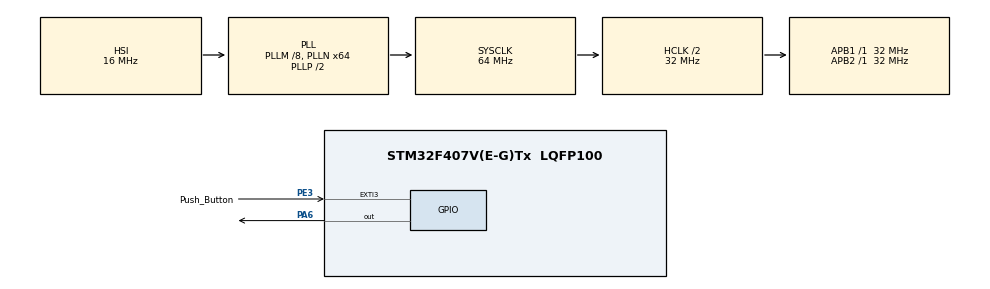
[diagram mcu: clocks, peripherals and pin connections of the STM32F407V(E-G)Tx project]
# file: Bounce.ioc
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Mcu.Family=STM32F4
Mcu.Name=STM32F407V(E-G)Tx
Mcu.Package=LQFP100
NVIC.EXTI3_IRQn=true\:0\:0\:false\:false\:true\:true\:true\:true
NVIC.PriorityGroup=NVIC_PRIORITYGROUP_4
NVIC.TIM1_BRK_TIM9_IRQn=true\:0\:0\:false\:false\:true\:true\:true\:true
NVIC.TIM1_CC_IRQn=true\:0\:0\:false\:false\:true\:true\:true\:true
NVIC.TIM1_TRG_COM_TIM11_IRQn=true\:0\:0\:false\:false\:true\:true\:true\:true
NVIC.TIM1_UP_TIM10_IRQn=true\:0\:0\:false\:false\:true\:true\:true\:true
PA13.Mode=Serial_Wire
PA13.Signal=SYS_JTMS-SWDIO
PA14.Mode=Serial_Wire
PA14.Signal=SYS_JTCK-SWCLK
PA6.PinState=GPIO_PIN_SET
PA6.Signal=GPIO_Output
PE3.GPIO_Label=Push_Button
PE3.GPIO_ModeDefaultEXTI=GPIO_MODE_IT_FALLING
PE3.GPIO_PuPd=GPIO_PULLUP
PE3.Signal=GPXTI3
PH0-OSC_IN.Mode=HSE-External-Oscillator
PH0-OSC_IN.Signal=RCC_OSC_IN
PH1-OSC_OUT.Mode=HSE-External-Oscillator
PH1-OSC_OUT.Signal=RCC_OSC_OUT
ProjectManager.HeapSize=0x200
ProjectManager.StackSize=0x400
ProjectManager.TargetToolchain=STM32CubeIDE
RCC.48MHZClocksFreq_Value=32000000
RCC.AHBCLKDivider=RCC_SYSCLK_DIV2
RCC.AHBFreq_Value=32000000
RCC.APB1Freq_Value=32000000
RCC.APB1TimFreq_Value=32000000
RCC.APB2Freq_Value=32000000
RCC.APB2TimFreq_Value=32000000
RCC.CortexFreq_Value=32000000
RCC.HCLKFreq_Value=32000000
RCC.HSE_VALUE=8000000
RCC.HSI_VALUE=16000000
RCC.LSE_VALUE=32768
RCC.PLLM=8
RCC.PLLN=64
RCC.SYSCLKFreq_VALUE=64000000
RCC.SYSCLKSource=RCC_SYSCLKSOURCE_PLLCLK
RCC.VCOOutputFreq_Value=128000000
TIM1.Period=50
TIM1.Prescaler=31999
VP_TIM1_VS_ClockSourceINT.Mode=Internal
VP_TIM1_VS_OPM.Mode=OPM_bit
board=custom

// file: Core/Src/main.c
/* USER CODE BEGIN Header */
/**
  ******************************************************************************
  * @file           : main.c
  * @brief          : Main program body
  ******************************************************************************
  * @attention
  *
  * Copyright (c) 2025 STMicroelectronics.
  * All rights reserved.
  *
  * This software is licensed under terms that can be found in the LICENSE file
  * in the root directory of this software component.
  * If no LICENSE file comes with this software, it is provided AS-IS.
  *
  ******************************************************************************
  */
/* USER CODE END Header */
#include "main.h"

/* USER CODE BEGIN Includes */
#include <stdbool.h>
/* USER CODE END Includes */

TIM_HandleTypeDef htim1;

void SystemClock_Config(void);
static void MX_GPIO_Init(void);
static void MX_TIM1_Init(void);
/* USER CODE BEGIN PFP */
bool state = true;
void HAL_GPIO_EXTI_Callback(uint16_t GPIO_Pin)
{
	if (GPIO_Pin == Push_Button_Pin && state == true)
	{
		HAL_TIM_Base_Start_IT(&htim1);
		state = false;
	}
	else
	{
		__NOP();
	}

	return;
}

void HAL_TIM_PeriodElapsedCallback(TIM_HandleTypeDef *htim)
{
	UNUSED(htim);

	if (HAL_GPIO_ReadPin(Push_Button_GPIO_Port, Push_Button_Pin) == GPIO_PIN_RESET)
	{
		HAL_GPIO_TogglePin(GPIOA, GPIO_PIN_6);
		state = true;
		HAL_TIM_Base_Stop_IT(&htim1);
	}

	return;
}
/* USER CODE END PFP */

int main(void)
{

  /* MCU Configuration--------------------------------------------------------*/

  /* Reset of all peripherals, Initializes the Flash interface and the Systick. */
  HAL_Init();

  /* Configure the system clock */
  SystemClock_Config();

  /* Initialize all configured peripherals */
  MX_GPIO_Init();
  MX_TIM1_Init();

  /* Infinite loop */
  while (1)
  {

  }
}

void SystemClock_Config(void)
{
  RCC_OscInitTypeDef RCC_OscInitStruct = {0};
  RCC_ClkInitTypeDef RCC_ClkInitStruct = {0};

  /** Configure the main internal regulator output voltage
  */
  __HAL_RCC_PWR_CLK_ENABLE();
  __HAL_PWR_VOLTAGESCALING_CONFIG(PWR_REGULATOR_VOLTAGE_SCALE1);

  /** Initializes the RCC Oscillators according to the specified parameters
  * in the RCC_OscInitTypeDef structure.
  */
  RCC_OscInitStruct.OscillatorType = RCC_OSCILLATORTYPE_HSI;
  RCC_OscInitStruct.HSIState = RCC_HSI_ON;
  RCC_OscInitStruct.HSICalibrationValue = RCC_HSICALIBRATION_DEFAULT;
  RCC_OscInitStruct.PLL.PLLState = RCC_PLL_ON;
  RCC_OscInitStruct.PLL.PLLSource = RCC_PLLSOURCE_HSI;
  RCC_OscInitStruct.PLL.PLLM = 8;
  RCC_OscInitStruct.PLL.PLLN = 64;
  RCC_OscInitStruct.PLL.PLLP = RCC_PLLP_DIV2;
  RCC_OscInitStruct.PLL.PLLQ = 4;
  if (HAL_RCC_OscConfig(&RCC_OscInitStruct) != HAL_OK)
  {
    Error_Handler();
  }

  /** Initializes the CPU, AHB and APB buses clocks
  */
  RCC_ClkInitStruct.ClockType = RCC_CLOCKTYPE_HCLK|RCC_CLOCKTYPE_SYSCLK
                              |RCC_CLOCKTYPE_PCLK1|RCC_CLOCKTYPE_PCLK2;
  RCC_ClkInitStruct.SYSCLKSource = RCC_SYSCLKSOURCE_PLLCLK;
  RCC_ClkInitStruct.AHBCLKDivider = RCC_SYSCLK_DIV2;
  RCC_ClkInitStruct.APB1CLKDivider = RCC_HCLK_DIV1;
  RCC_ClkInitStruct.APB2CLKDivider = RCC_HCLK_DIV1;

  if (HAL_RCC_ClockConfig(&RCC_ClkInitStruct, FLASH_LATENCY_1) != HAL_OK)
  {
    Error_Handler();
  }
}

static void MX_TIM1_Init(void)
{

  TIM_ClockConfigTypeDef sClockSourceConfig = {0};
  TIM_MasterConfigTypeDef sMasterConfig = {0};

  htim1.Instance = TIM1;
  htim1.Init.Prescaler = 31999;
  htim1.Init.CounterMode = TIM_COUNTERMODE_UP;
  htim1.Init.Period = 50;
  htim1.Init.ClockDivision = TIM_CLOCKDIVISION_DIV1;
  htim1.Init.RepetitionCounter = 0;
  htim1.Init.AutoReloadPreload = TIM_AUTORELOAD_PRELOAD_DISABLE;
  if (HAL_TIM_Base_Init(&htim1) != HAL_OK)
  {
    Error_Handler();
  }
  sClockSourceConfig.ClockSource = TIM_CLOCKSOURCE_INTERNAL;
  if (HAL_TIM_ConfigClockSource(&htim1, &sClockSourceConfig) != HAL_OK)
  {
    Error_Handler();
  }
  if (HAL_TIM_OnePulse_Init(&htim1, TIM_OPMODE_SINGLE) != HAL_OK)
  {
    Error_Handler();
  }
  sMasterConfig.MasterOutputTrigger = TIM_TRGO_RESET;
  sMasterConfig.MasterSlaveMode = TIM_MASTERSLAVEMODE_DISABLE;
  if (HAL_TIMEx_MasterConfigSynchronization(&htim1, &sMasterConfig) != HAL_OK)
  {
    Error_Handler();
  }

}

static void MX_GPIO_Init(void)
{
  GPIO_InitTypeDef GPIO_InitStruct = {0};

  /* GPIO Ports Clock Enable */
  __HAL_RCC_GPIOE_CLK_ENABLE();
  __HAL_RCC_GPIOH_CLK_ENABLE();
  __HAL_RCC_GPIOA_CLK_ENABLE();

  /*Configure GPIO pin Output Level */
  HAL_GPIO_WritePin(GPIOA, GPIO_PIN_6, GPIO_PIN_SET);

  /*Configure GPIO pin : Push_Button_Pin */
  GPIO_InitStruct.Pin = Push_Button_Pin;
  GPIO_InitStruct.Mode = GPIO_MODE_IT_FALLING;
  GPIO_InitStruct.Pull = GPIO_PULLUP;
  HAL_GPIO_Init(Push_Button_GPIO_Port, &GPIO_InitStruct);

  /*Configure GPIO pin : PA6 */
  GPIO_InitStruct.Pin = GPIO_PIN_6;
  GPIO_InitStruct.Mode = GPIO_MODE_OUTPUT_PP;
  GPIO_InitStruct.Pull = GPIO_NOPULL;
  GPIO_InitStruct.Speed = GPIO_SPEED_FREQ_LOW;
  HAL_GPIO_Init(GPIOA, &GPIO_InitStruct);

  /* EXTI interrupt init*/
  HAL_NVIC_SetPriority(EXTI3_IRQn, 0, 0);
  HAL_NVIC_EnableIRQ(EXTI3_IRQn);

}

void Error_Handler(void)
{
  __disable_irq();
  while (1)
  {
  }
}
